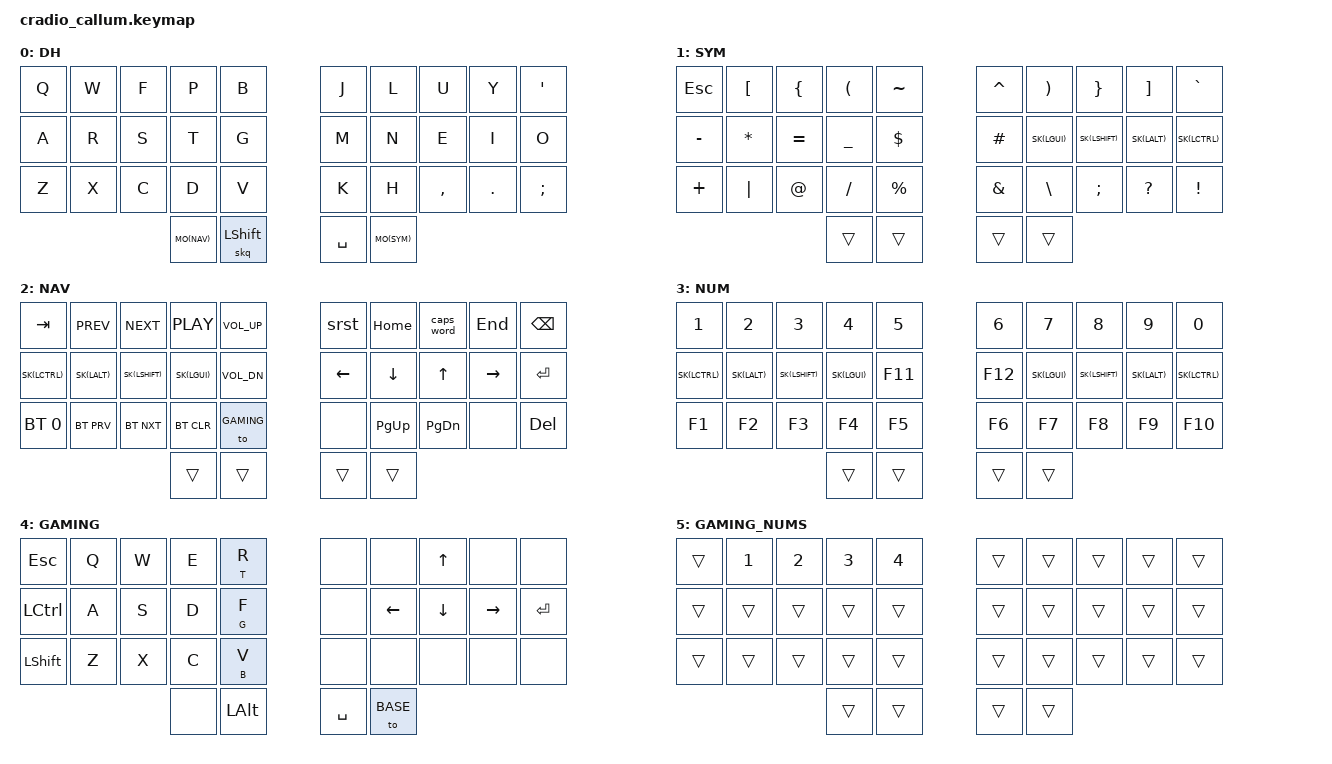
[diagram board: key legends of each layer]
// Some ideas borrowed from

// https://github.com/callum-oakley/keymap
// https://github.com/dxmh/zmk-config/
// https://github.com/caksoylar/zmk-config/blob/main/config/3x5%2B2.keymap
#include <behaviors.dtsi>
#include <dt-bindings/zmk/keys.h>
#include <dt-bindings/zmk/bt.h>
#include <dt-bindings/zmk/outputs.h>

#define XXX &none
#define ___ &trans

#define BASE 0
#define SYM 1
#define NAV 2
#define NUM 3
#define GAMING 4
#define GNUM 5

#define SK(KEY) &nk KEY KEY
#define MO(LAYER) &mo_tap LAYER F24
#define STICKY_KEY_TIMEOUT 60000

#define COMBO(NAME, BINDINGS, KEYPOS, LAYERS) \
  combo_##NAME { \
    bindings = <BINDINGS>; \
    key-positions = <KEYPOS>; \
    layers = <LAYERS>; \
  };

&sk {
  release-after-ms = <STICKY_KEY_TIMEOUT>;
};

&caps_word {
  continue-list = <UNDERSCORE MINUS BACKSPACE>;
};

&kscan0 {
  debounce-period = <14>;
};

/ {

  combos {
    compatible = "zmk,combos";

/*                KEY POSITIONS

  ╭────────────────────╮ ╭────────────────────╮
  │  0   1   2   3   4 │ │  5   6   7   8   9 │
  │ 10  11  12  13  14 │ │ 15  16  17  18  19 │
  │ 20  21  22  23  24 │ │ 25  26  27  28  29 │
  ╰───────────╮ 30  31 │ │ 32  33 ╭───────────╯
              ╰────────╯ ╰────────╯            */

    COMBO(esc, &kp ESC, 0 1, BASE)
    COMBO(stab, &kp LS(TAB), 10 11, BASE)
    COMBO(tab, &kp TAB, 12 13, BASE)
    COMBO(meta, SK(LGUI), 20 21, BASE)


    COMBO(altgr, SK(RALT), 27 28, BASE SYM NUM)
    COMBO(bsp, &kp BSPC, 8 9, BASE)
    COMBO(entr, &kp ENTER, 18 19, BASE)
    COMBO(del, &kp DEL, 28 29, BASE)

  };

  behaviors {
     srst: smart_reset {
         compatible = "zmk,behavior-tap-dance";
         label = "SMART_RESERT";
         #binding-cells = <0>;
         tapping-term-ms = <200>;
         bindings = <&reset>, <&bootloader>;
    };
    th: tab_hold {
        compatible = "zmk,behavior-hold-tap";
        label = "TAB_HOLD";
        #binding-cells = <2>;
        tapping-term-ms = <150>;
        quick_tap_ms = <0>;
        flavor = "tap-preferred";
        bindings = <&kp>, <&kp>;
    };

    skq: sticky_key_quick_release {
      compatible = "zmk,behavior-sticky-key";
      label = "STICKY_KEY_QUICK_RELEASE";
      #binding-cells = <1>;
      bindings = <&kp>;
      quick-release;
      release-after-ms = <STICKY_KEY_TIMEOUT>;
    };
    tssa: tap-shift-altgr {
      compatible = "zmk,behavior-tap-dance";
      label = "TAP-SHIFT-ALTGR";
      #binding-cells = <0>;
      bindings = <&skq LSHIFT>, <&sk LALT>;
    };

    // Useful for modifier-clicking without the modifier remaining active
    nk: not_so_sticky_key {
      compatible = "zmk,behavior-hold-tap";
      label = "NOT_SO_STICKY_KEY";
      #binding-cells = <2>;
      tapping_term_ms = <200>;
      flavor = "tap-preferred";
      bindings = <&kp>, <&sk>;
    };

    // A hold-tap that activates without delay (like `&mo`)
    mo_tap: mo_with_tap {
      compatible = "zmk,behavior-hold-tap";
      label = "MO_WITH_TAP";
      #binding-cells = <2>;
      tapping_term_ms = <0>;
      retro-tap;
      flavor = "hold-preferred";
      bindings = <&mo>, <&kp>;
    };


  };
  cond_layers {
      compatible = "zmk,conditional-layers";
      func_tristate {
          if-layers = <NAV SYM>;
          then-layer = <NUM>;
      };
  };

  keymap {
    compatible = "zmk,keymap";

    /* base_layer { */
    /*   label = "QUERTY"; */
    /*   bindings = < */
    /*     // ╭─────────────┬─────────────┬─────────────┬─────────────┬─────────────╮   ╭─────────────┬─────────────┬────────────────┬─────────────┬────────────────╮ */
    /*          &kp Q         &kp W         &kp E         &kp R         &kp T             &kp Y         &kp U         &kp I            &kp O         &kp P */
    /*     // ├─────────────┼─────────────┼─────────────┼─────────────┼─────────────┤   ├─────────────┼─────────────┼────────────────┼─────────────┼────────────────┤ */
    /*          &kp A         &kp S         &kp D         &kp F         &kp G             &kp H         &kp J         &kp K            &kp L         &kp SQT */
    /*     // ├─────────────┼─────────────┼─────────────┼─────────────┼─────────────┤   ├─────────────┼─────────────┼────────────────┼─────────────┼────────────────┤ */
    /*          &kp Z         &kp X         &kp C         &kp V         &kp B             &kp N         &kp M         &kp COMMA        &kp DOT       &kp SEMI */
    /*     // ╰─────────────┴─────────────┴─────────────┼─────────────┼─────────────┤   ├─────────────┼─────────────┼────────────────┴─────────────┴────────────────╯ */
    /*                                                    MO(NAV)       &tssa             &kp SPACE     MO(SYM) */
    /*     //                                           ╰─────────────┴─────────────╯   ╰─────────────┴─────────────╯ */
    /*   >; */
    /* }; */

    colemak_layer {
      label = "DH";
      bindings = <
        // ╭─────────────┬─────────────┬─────────────┬─────────────┬─────────────╮   ╭─────────────┬─────────────┬─────────────┬─────────────┬─────────────╮
             &kp Q         &kp W         &kp F         &kp P         &kp B             &kp J         &kp L         &kp U         &kp Y         &kp SQT
        // ├─────────────┼─────────────┼─────────────┼─────────────┼─────────────┤   ├─────────────┼─────────────┼─────────────┼─────────────┼─────────────┤
             &kp A         &kp R         &kp S         &kp T         &kp G             &kp M         &kp N         &kp E         &kp I         &kp O
        // ├─────────────┼─────────────┼─────────────┼─────────────┼─────────────┤   ├─────────────┼─────────────┼─────────────┼─────────────┼─────────────┤
             &kp Z         &kp X         &kp C         &kp D         &kp V             &kp K         &kp H         &kp COMMA     &kp DOT       &kp SEMI
        // ╰─────────────┴─────────────┴─────────────┼─────────────┼─────────────┤   ├─────────────┼─────────────┼─────────────┴─────────────┴─────────────╯
                                                       MO(NAV)       &skq LSHIFT       &kp SPACE     MO(SYM)
        //                                           ╰─────────────┴─────────────╯   ╰─────────────┴─────────────╯
      >;
    };

    sym_layer {
      label = "SYM";
      bindings = <
        // ╭─────────────┬─────────────┬─────────────┬─────────────┬─────────────╮   ╭─────────────┬─────────────┬─────────────┬─────────────┬────────────────╮
             &kp ESC        &kp LBKT     &kp LBRC      &kp LPAR      &kp TILDE         &kp CARET     &kp RPAR      &kp RBRC      &kp RBKT      &kp GRAVE
        // ├─────────────┼─────────────┼─────────────┼─────────────┼─────────────┤   ├─────────────┼─────────────┼─────────────┼─────────────┼────────────────┤
             &kp MINUS      &kp STAR     &kp EQUAL     &kp UNDER     &kp DOLLAR        &kp HASH      SK(LGUI)      SK(LSHIFT)    SK(LALT)      SK(LCTRL)
        // ├─────────────┼─────────────┼─────────────┼─────────────┼─────────────┤   ├─────────────┼─────────────┼─────────────┼─────────────┼────────────────┤
             &kp PLUS        &kp PIPE     &kp AT      &kp FSLH      &kp PERCENT        &kp AMPS      &kp BSLH      &kp SEMI      &kp QMARK     &kp EXCL
        // ╰─────────────┴─────────────┴─────────────┼─────────────┼─────────────┤   ├─────────────┼─────────────┼─────────────┴─────────────┴────────────────╯
                                                       ___           ___               ___           ___
        //                                           ╰─────────────┴─────────────╯   ╰─────────────┴─────────────╯
      >;
    };

    nav_layer {
      label = "NAV";
      bindings = <
        // ╭─────────────┬─────────────┬─────────────┬─────────────┬─────────────╮   ╭─────────────┬─────────────┬─────────────┬─────────────┬────────────────╮
             &kp TAB       &kp C_PREV    &kp C_NEXT    &kp C_PLAY    &kp C_VOL_UP      &srst         &kp HOME      &caps_word    &kp END       &kp BSPC
        // ├─────────────┼─────────────┼─────────────┼─────────────┼─────────────┤   ├─────────────┼─────────────┼─────────────┼─────────────┼────────────────┤
             SK(LCTRL)     SK(LALT)      SK(LSHIFT)    SK(LGUI)      &kp C_VOL_DN      &kp LEFT      &kp DOWN     &kp UP      &kp RIGHT        &kp ENTER
        // ├─────────────┼─────────────┼─────────────┼─────────────┼─────────────┤   ├─────────────┼─────────────┼─────────────┼─────────────┼────────────────┤
             &bt BT_SEL 0  &bt BT_PRV    &bt BT_NXT    &bt BT_CLR    &to GAMING        XXX           &kp PG_UP     &kp PG_DN     XXX           &kp DEL
        // ╰─────────────┴─────────────┴─────────────┼─────────────┼─────────────┤   ├─────────────┼─────────────┼─────────────┴─────────────┴────────────────╯
                                                       ___           ___               ___           ___
        //                                           ╰─────────────┴─────────────╯   ╰─────────────┴─────────────╯
      >;
    };

    num_layer {
      label = "NUM";
      bindings = <
        // ╭─────────────┬─────────────┬─────────────┬─────────────┬─────────────╮   ╭─────────────┬─────────────┬─────────────┬─────────────┬────────────────╮
             &kp N1        &kp N2        &kp N3        &kp N4        &kp N5            &kp N6        &kp N7        &kp N8        &kp N9        &kp N0
        // ├─────────────┼─────────────┼─────────────┼─────────────┼─────────────┤   ├─────────────┼─────────────┼─────────────┼─────────────┼────────────────┤
             SK(LCTRL)     SK(LALT)      SK(LSHIFT)    SK(LGUI)      &kp F11           &kp F12        SK(LGUI)      SK(LSHIFT)    SK(LALT)      SK(LCTRL)
        // ├─────────────┼─────────────┼─────────────┼─────────────┼─────────────┤   ├─────────────┼─────────────┼─────────────┼─────────────┼────────────────┤
             &kp F1        &kp F2        &kp F3        &kp F4        &kp F5            &kp F6         &kp F7       &kp F8        &kp F9        &kp F10
        // ╰─────────────┴─────────────┴─────────────┼─────────────┼─────────────┤   ├─────────────┼─────────────┼─────────────┴─────────────┴────────────────╯
                                                       ___           ___               ___           ___
        //                                           ╰─────────────┴─────────────╯   ╰─────────────┴─────────────╯
      >;
    };
    /* ---------------------  These layers are just for playing so they are focused on left hand  ---------------------- */
    gaming_layer {
      label = "GAMING";
      bindings = <
        // ╭─────────────┬─────────────┬─────────────┬─────────────┬─────────────╮   ╭─────────────┬─────────────┬─────────────┬─────────────────┬────────────────╮
              &kp ESC      &kp Q         &kp W         &kp E         &th T R           XXX          XXX          &kp UP        XXX                XXX
        // ├─────────────┼─────────────┼─────────────┼─────────────┼─────────────┤   ├─────────────┼─────────────┼─────────────┼─────────────────┼────────────────┤
              &kp LCTRL    &kp A         &kp S         &kp D         &th G F           XXX          &kp LEFT      &kp DOWN      &kp RIGHT         &kp ENTER
        // ├─────────────┼─────────────┼─────────────┼─────────────┼─────────────┤   ├─────────────┼─────────────┼─────────────┼─────────────────┼────────────────┤
              &kp LSHIFT   &kp Z         &kp X         &kp C         &th B V           XXX          XXX           XXX           XXX               XXX
        // ╰─────────────┴─────────────┴─────────────┼─────────────┼─────────────┤   ├─────────────┼─────────────┼─────────────┴─────────────────┴────────────────╯
                                                        XXX          &kp LALT          &kp SPACE     &to BASE
        //                                           ╰─────────────┴─────────────╯   ╰─────────────┴─────────────╯
      >;
    };

    gaming_nums_layer {
      label = "GAMING_NUMS";
      bindings = <
        // ╭─────────────┬─────────────┬─────────────┬─────────────┬─────────────╮   ╭─────────────┬─────────────┬─────────────┬─────────────────┬────────────────╮
              ___          &kp N1        &kp N2        &kp N3        &kp N4            ___           ___           ___           ___               ___
        // ├─────────────┼─────────────┼─────────────┼─────────────┼─────────────┤   ├─────────────┼─────────────┼─────────────┼─────────────────┼────────────────┤
              ___          ___           ___           ___           ___               ___           ___           ___           ___               ___
        // ├─────────────┼─────────────┼─────────────┼─────────────┼─────────────┤   ├─────────────┼─────────────┼─────────────┼─────────────────┼────────────────┤
              ___          ___           ___           ___           ___               ___           ___           ___           ___               ___
        // ╰─────────────┴─────────────┴─────────────┼─────────────┼─────────────┤   ├─────────────┼─────────────┼─────────────┴─────────────────┴────────────────╯
                                                       ___           ___               ___          ___
        //                                           ╰─────────────┴─────────────╯   ╰─────────────┴─────────────╯
      >;
    };


  };
};
